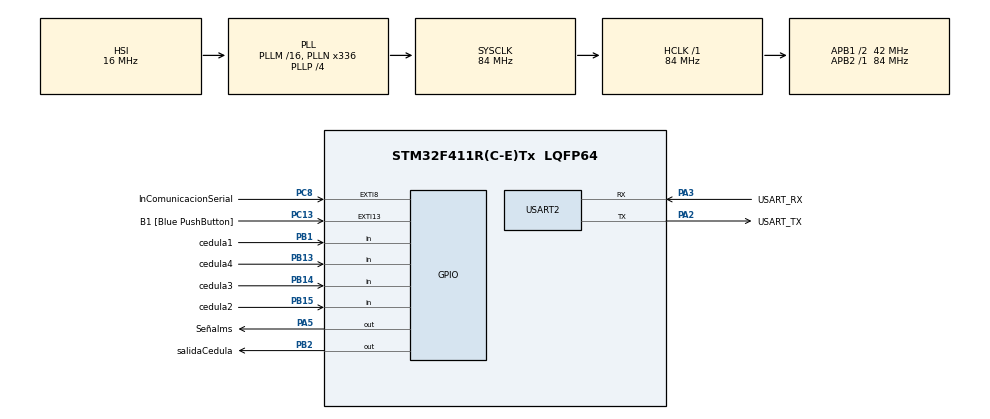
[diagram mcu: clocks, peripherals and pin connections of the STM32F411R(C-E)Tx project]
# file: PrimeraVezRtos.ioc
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FREERTOS.Tasks01=Task1,24,128,SenalCuadrada,Default,NULL,Dynamic,NULL,NULL;Task2,8,128,Cedula,Default,NULL,Dynamic,NULL,NULL;Task3,8,128,Receptor,Default,NULL,Dynamic,NULL,NULL
Mcu.Family=STM32F4
Mcu.Name=STM32F411R(C-E)Tx
Mcu.Package=LQFP64
NVIC.EXTI9_5_IRQn=true\:0\:0\:false\:false\:true\:false\:true\:true\:true
NVIC.PriorityGroup=NVIC_PRIORITYGROUP_4
NVIC.TIM1_TRG_COM_TIM11_IRQn=true\:15\:0\:false\:false\:true\:false\:false\:true\:true
NVIC.TIM3_IRQn=true\:5\:0\:false\:false\:true\:true\:true\:true\:true
NVIC.TIM4_IRQn=true\:5\:0\:false\:false\:true\:true\:true\:true\:true
NVIC.TIM5_IRQn=true\:5\:0\:false\:false\:true\:true\:true\:true\:true
NVIC.TimeBase=TIM1_TRG_COM_TIM11_IRQn
NVIC.TimeBaseIP=TIM11
PA13.GPIO_Label=TMS
PA13.Mode=Trace_Asynchronous_SW
PA13.Signal=SYS_JTMS-SWDIO
PA14.GPIO_Label=TCK
PA14.Mode=Trace_Asynchronous_SW
PA14.Signal=SYS_JTCK-SWCLK
PA2.GPIO_Label=USART_TX
PA2.Mode=Asynchronous
PA2.Signal=USART2_TX
PA3.GPIO_Label=USART_RX
PA3.Mode=Asynchronous
PA3.Signal=USART2_RX
PA5.GPIO_Label=Se\u00F1alms
PA5.GPIO_Speed=GPIO_SPEED_FREQ_HIGH
PA5.Signal=GPIO_Output
PB1.GPIO_Label=cedula1
PB1.GPIO_PuPd=GPIO_PULLDOWN
PB1.Signal=GPIO_Input
PB13.GPIO_Label=cedula4
PB13.GPIO_PuPd=GPIO_PULLDOWN
PB13.Signal=GPIO_Input
PB14.GPIO_Label=cedula3
PB14.GPIO_PuPd=GPIO_PULLDOWN
PB14.Signal=GPIO_Input
PB15.GPIO_Label=cedula2
PB15.GPIO_PuPd=GPIO_PULLDOWN
PB15.Signal=GPIO_Input
PB2.GPIO_Label=salidaCedula
PB2.Signal=GPIO_Output
PB3.GPIO_Label=SWO
PB3.Mode=Trace_Asynchronous_SW
PB3.Signal=SYS_JTDO-SWO
PC13-ANTI_TAMP.GPIO_Label=B1 [Blue PushButton]
PC13-ANTI_TAMP.GPIO_ModeDefaultEXTI=GPIO_MODE_IT_FALLING
PC13-ANTI_TAMP.Signal=GPXTI13
PC14-OSC32_IN.Mode=LSE-External-Oscillator
PC14-OSC32_IN.Signal=RCC_OSC32_IN
PC15-OSC32_OUT.Mode=LSE-External-Oscillator
PC15-OSC32_OUT.Signal=RCC_OSC32_OUT
PC8.GPIO_Label=InComunicacionSerial
PC8.GPIO_ModeDefaultEXTI=GPIO_MODE_IT_FALLING
PC8.Signal=GPXTI8
PH0\ -\ OSC_IN.Mode=HSE-External-Clock-Source
PH0\ -\ OSC_IN.Signal=RCC_OSC_IN
PH1\ -\ OSC_OUT.Mode=HSE-External-Clock-Source
PH1\ -\ OSC_OUT.Signal=RCC_OSC_OUT
ProjectManager.HeapSize=0x200
ProjectManager.StackSize=0x400
ProjectManager.TargetToolchain=STM32CubeIDE
RCC.48MHZClocksFreq_Value=84000000
RCC.AHBFreq_Value=84000000
RCC.APB1CLKDivider=RCC_HCLK_DIV2
RCC.APB1Freq_Value=42000000
RCC.APB1TimFreq_Value=84000000
RCC.APB2Freq_Value=84000000
RCC.APB2TimFreq_Value=84000000
RCC.CortexFreq_Value=84000000
RCC.FLatency-AdvancedSettings=FLASH_LATENCY_2
RCC.HCLKFreq_Value=84000000
RCC.HSE_VALUE=8000000
RCC.HSI_VALUE=16000000
RCC.PLLN=336
RCC.PLLP=RCC_PLLP_DIV4
RCC.SYSCLKFreq_VALUE=84000000
RCC.SYSCLKSource=RCC_SYSCLKSOURCE_PLLCLK
RCC.VCOOutputFreq_Value=336000000
TIM3.AutoReloadPreload=TIM_AUTORELOAD_PRELOAD_ENABLE
TIM3.Period=9000
TIM3.Prescaler=84
TIM4.AutoReloadPreload=TIM_AUTORELOAD_PRELOAD_ENABLE
TIM4.Period=50000
TIM4.Prescaler=84
TIM5.AutoReloadPreload=TIM_AUTORELOAD_PRELOAD_ENABLE
TIM5.Period=208
TIM5.Prescaler=84
USART2.VirtualMode=VM_ASYNC
VP_FREERTOS_VS_CMSIS_V2.Mode=CMSIS_V2
VP_SYS_VS_tim11.Mode=TIM11
VP_TIM3_VS_ClockSourceINT.Mode=Internal
VP_TIM4_VS_ClockSourceINT.Mode=Internal
VP_TIM5_VS_ClockSourceINT.Mode=Internal
board=NUCLEO-F411RE

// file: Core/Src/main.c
/* USER CODE BEGIN Header */
/**
  ******************************************************************************
  * @file           : main.c
  * @brief          : Main program body
  ******************************************************************************
  * @attention
  *
  * Copyright (c) 2023 STMicroelectronics.
  * All rights reserved.
  *
  * This software is licensed under terms that can be found in the LICENSE file
  * in the root directory of this software component.
  * If no LICENSE file comes with this software, it is provided AS-IS.
  *
  ******************************************************************************
  */
/* USER CODE END Header */
#include "main.h"
#include "cmsis_os.h"

TIM_HandleTypeDef htim3;
TIM_HandleTypeDef htim4;
TIM_HandleTypeDef htim5;

UART_HandleTypeDef huart2;

/* Definitions for Task1 */
osThreadId_t Task1Handle;
const osThreadAttr_t Task1_attributes = {
  .name = "Task1",
  .stack_size = 128 * 4,
  .priority = (osPriority_t) osPriorityNormal,
};
/* Definitions for Task2 */
osThreadId_t Task2Handle;
const osThreadAttr_t Task2_attributes = {
  .name = "Task2",
  .stack_size = 128 * 4,
  .priority = (osPriority_t) osPriorityLow,
};
/* Definitions for Task3 */
osThreadId_t Task3Handle;
const osThreadAttr_t Task3_attributes = {
  .name = "Task3",
  .stack_size = 128 * 4,
  .priority = (osPriority_t) osPriorityLow,
};

void SystemClock_Config(void);
static void MX_GPIO_Init(void);
static void MX_USART2_UART_Init(void);
static void MX_TIM3_Init(void);
static void MX_TIM4_Init(void);
static void MX_TIM5_Init(void);
void SenalCuadrada(void *argument);
void Cedula(void *argument);
void Receptor(void *argument);

/* USER CODE BEGIN PFP */
uint8_t A = 0, B = 0, C = 0, D = 0, imprimir = 0;
int contComunicacionTimer = 0, contComunicacionGPIO = 1, cambioARR = 1;
char buffer[40];
int data[9];
/* USER CODE END PFP */

int main(void)
{

  /* MCU Configuration--------------------------------------------------------*/

  /* Reset of all peripherals, Initializes the Flash interface and the Systick. */
  HAL_Init();

  /* Configure the system clock */
  SystemClock_Config();

  /* Initialize all configured peripherals */
  MX_GPIO_Init();
  MX_USART2_UART_Init();
  MX_TIM3_Init();
  MX_TIM4_Init();
  MX_TIM5_Init();

  /* Init scheduler */
  osKernelInitialize();

  /* Create the thread(s) */
  /* creation of Task1 */
  Task1Handle = osThreadNew(SenalCuadrada, NULL, &Task1_attributes);

  /* creation of Task2 */
  Task2Handle = osThreadNew(Cedula, NULL, &Task2_attributes);

  /* creation of Task3 */
  Task3Handle = osThreadNew(Receptor, NULL, &Task3_attributes);

  /* Start scheduler */
  osKernelStart();

  /* We should never get here as control is now taken by the scheduler */
  /* Infinite loop */
  while (1)
  {
  }
}

void SystemClock_Config(void)
{
  RCC_OscInitTypeDef RCC_OscInitStruct = {0};
  RCC_ClkInitTypeDef RCC_ClkInitStruct = {0};

  /** Configure the main internal regulator output voltage
  */
  __HAL_RCC_PWR_CLK_ENABLE();
  __HAL_PWR_VOLTAGESCALING_CONFIG(PWR_REGULATOR_VOLTAGE_SCALE1);

  /** Initializes the RCC Oscillators according to the specified parameters
  * in the RCC_OscInitTypeDef structure.
  */
  RCC_OscInitStruct.OscillatorType = RCC_OSCILLATORTYPE_HSI;
  RCC_OscInitStruct.HSIState = RCC_HSI_ON;
  RCC_OscInitStruct.HSICalibrationValue = RCC_HSICALIBRATION_DEFAULT;
  RCC_OscInitStruct.PLL.PLLState = RCC_PLL_ON;
  RCC_OscInitStruct.PLL.PLLSource = RCC_PLLSOURCE_HSI;
  RCC_OscInitStruct.PLL.PLLM = 16;
  RCC_OscInitStruct.PLL.PLLN = 336;
  RCC_OscInitStruct.PLL.PLLP = RCC_PLLP_DIV4;
  RCC_OscInitStruct.PLL.PLLQ = 4;
  if (HAL_RCC_OscConfig(&RCC_OscInitStruct) != HAL_OK)
  {
    Error_Handler();
  }

  /** Initializes the CPU, AHB and APB buses clocks
  */
  RCC_ClkInitStruct.ClockType = RCC_CLOCKTYPE_HCLK|RCC_CLOCKTYPE_SYSCLK
                              |RCC_CLOCKTYPE_PCLK1|RCC_CLOCKTYPE_PCLK2;
  RCC_ClkInitStruct.SYSCLKSource = RCC_SYSCLKSOURCE_PLLCLK;
  RCC_ClkInitStruct.AHBCLKDivider = RCC_SYSCLK_DIV1;
  RCC_ClkInitStruct.APB1CLKDivider = RCC_HCLK_DIV2;
  RCC_ClkInitStruct.APB2CLKDivider = RCC_HCLK_DIV1;

  if (HAL_RCC_ClockConfig(&RCC_ClkInitStruct, FLASH_LATENCY_2) != HAL_OK)
  {
    Error_Handler();
  }
}

static void MX_TIM3_Init(void)
{

  TIM_ClockConfigTypeDef sClockSourceConfig = {0};
  TIM_MasterConfigTypeDef sMasterConfig = {0};

  htim3.Instance = TIM3;
  htim3.Init.Prescaler = 84;
  htim3.Init.CounterMode = TIM_COUNTERMODE_UP;
  htim3.Init.Period = 9000;
  htim3.Init.ClockDivision = TIM_CLOCKDIVISION_DIV1;
  htim3.Init.AutoReloadPreload = TIM_AUTORELOAD_PRELOAD_ENABLE;
  if (HAL_TIM_Base_Init(&htim3) != HAL_OK)
  {
    Error_Handler();
  }
  sClockSourceConfig.ClockSource = TIM_CLOCKSOURCE_INTERNAL;
  if (HAL_TIM_ConfigClockSource(&htim3, &sClockSourceConfig) != HAL_OK)
  {
    Error_Handler();
  }
  sMasterConfig.MasterOutputTrigger = TIM_TRGO_RESET;
  sMasterConfig.MasterSlaveMode = TIM_MASTERSLAVEMODE_DISABLE;
  if (HAL_TIMEx_MasterConfigSynchronization(&htim3, &sMasterConfig) != HAL_OK)
  {
    Error_Handler();
  }

}

static void MX_TIM4_Init(void)
{

  TIM_ClockConfigTypeDef sClockSourceConfig = {0};
  TIM_MasterConfigTypeDef sMasterConfig = {0};

  htim4.Instance = TIM4;
  htim4.Init.Prescaler = 84;
  htim4.Init.CounterMode = TIM_COUNTERMODE_UP;
  htim4.Init.Period = 50000;
  htim4.Init.ClockDivision = TIM_CLOCKDIVISION_DIV1;
  htim4.Init.AutoReloadPreload = TIM_AUTORELOAD_PRELOAD_ENABLE;
  if (HAL_TIM_Base_Init(&htim4) != HAL_OK)
  {
    Error_Handler();
  }
  sClockSourceConfig.ClockSource = TIM_CLOCKSOURCE_INTERNAL;
  if (HAL_TIM_ConfigClockSource(&htim4, &sClockSourceConfig) != HAL_OK)
  {
    Error_Handler();
  }
  sMasterConfig.MasterOutputTrigger = TIM_TRGO_RESET;
  sMasterConfig.MasterSlaveMode = TIM_MASTERSLAVEMODE_DISABLE;
  if (HAL_TIMEx_MasterConfigSynchronization(&htim4, &sMasterConfig) != HAL_OK)
  {
    Error_Handler();
  }

}

static void MX_TIM5_Init(void)
{

  TIM_ClockConfigTypeDef sClockSourceConfig = {0};
  TIM_MasterConfigTypeDef sMasterConfig = {0};

  htim5.Instance = TIM5;
  htim5.Init.Prescaler = 84;
  htim5.Init.CounterMode = TIM_COUNTERMODE_UP;
  htim5.Init.Period = 208;
  htim5.Init.ClockDivision = TIM_CLOCKDIVISION_DIV1;
  htim5.Init.AutoReloadPreload = TIM_AUTORELOAD_PRELOAD_ENABLE;
  if (HAL_TIM_Base_Init(&htim5) != HAL_OK)
  {
    Error_Handler();
  }
  sClockSourceConfig.ClockSource = TIM_CLOCKSOURCE_INTERNAL;
  if (HAL_TIM_ConfigClockSource(&htim5, &sClockSourceConfig) != HAL_OK)
  {
    Error_Handler();
  }
  sMasterConfig.MasterOutputTrigger = TIM_TRGO_RESET;
  sMasterConfig.MasterSlaveMode = TIM_MASTERSLAVEMODE_DISABLE;
  if (HAL_TIMEx_MasterConfigSynchronization(&htim5, &sMasterConfig) != HAL_OK)
  {
    Error_Handler();
  }

}

static void MX_USART2_UART_Init(void)
{

  huart2.Instance = USART2;
  huart2.Init.BaudRate = 115200;
  huart2.Init.WordLength = UART_WORDLENGTH_8B;
  huart2.Init.StopBits = UART_STOPBITS_1;
  huart2.Init.Parity = UART_PARITY_NONE;
  huart2.Init.Mode = UART_MODE_TX_RX;
  huart2.Init.HwFlowCtl = UART_HWCONTROL_NONE;
  huart2.Init.OverSampling = UART_OVERSAMPLING_16;
  if (HAL_UART_Init(&huart2) != HAL_OK)
  {
    Error_Handler();
  }

}

static void MX_GPIO_Init(void)
{
  GPIO_InitTypeDef GPIO_InitStruct = {0};

  /* GPIO Ports Clock Enable */
  __HAL_RCC_GPIOC_CLK_ENABLE();
  __HAL_RCC_GPIOH_CLK_ENABLE();
  __HAL_RCC_GPIOA_CLK_ENABLE();
  __HAL_RCC_GPIOB_CLK_ENABLE();

  /*Configure GPIO pin Output Level */
  HAL_GPIO_WritePin(Se_alms_GPIO_Port, Se_alms_Pin, GPIO_PIN_RESET);

  /*Configure GPIO pin Output Level */
  HAL_GPIO_WritePin(salidaCedula_GPIO_Port, salidaCedula_Pin, GPIO_PIN_RESET);

  /*Configure GPIO pins : B1_Pin InComunicacionSerial_Pin */
  GPIO_InitStruct.Pin = B1_Pin|InComunicacionSerial_Pin;
  GPIO_InitStruct.Mode = GPIO_MODE_IT_FALLING;
  GPIO_InitStruct.Pull = GPIO_NOPULL;
  HAL_GPIO_Init(GPIOC, &GPIO_InitStruct);

  /*Configure GPIO pin : Se_alms_Pin */
  GPIO_InitStruct.Pin = Se_alms_Pin;
  GPIO_InitStruct.Mode = GPIO_MODE_OUTPUT_PP;
  GPIO_InitStruct.Pull = GPIO_NOPULL;
  GPIO_InitStruct.Speed = GPIO_SPEED_FREQ_HIGH;
  HAL_GPIO_Init(Se_alms_GPIO_Port, &GPIO_InitStruct);

  /*Configure GPIO pins : cedula1_Pin cedula4_Pin cedula3_Pin cedula2_Pin */
  GPIO_InitStruct.Pin = cedula1_Pin|cedula4_Pin|cedula3_Pin|cedula2_Pin;
  GPIO_InitStruct.Mode = GPIO_MODE_INPUT;
  GPIO_InitStruct.Pull = GPIO_PULLDOWN;
  HAL_GPIO_Init(GPIOB, &GPIO_InitStruct);

  /*Configure GPIO pin : salidaCedula_Pin */
  GPIO_InitStruct.Pin = salidaCedula_Pin;
  GPIO_InitStruct.Mode = GPIO_MODE_OUTPUT_PP;
  GPIO_InitStruct.Pull = GPIO_NOPULL;
  GPIO_InitStruct.Speed = GPIO_SPEED_FREQ_LOW;
  HAL_GPIO_Init(salidaCedula_GPIO_Port, &GPIO_InitStruct);

  /* EXTI interrupt init*/
  HAL_NVIC_SetPriority(EXTI9_5_IRQn, 0, 0);
  HAL_NVIC_EnableIRQ(EXTI9_5_IRQn);

}

void SenalCuadrada(void *argument){

  for(;;){
	HAL_GPIO_TogglePin(GPIOA, GPIO_PIN_5);
    osDelay(9);
  }
}

void Cedula(void *argument){

  for(;;){

	A = HAL_GPIO_ReadPin(GPIOB, GPIO_PIN_1);
	B = HAL_GPIO_ReadPin(GPIOB, GPIO_PIN_15);
	C = HAL_GPIO_ReadPin(GPIOB, GPIO_PIN_14);
	D = HAL_GPIO_ReadPin(GPIOB, GPIO_PIN_13); // bit derecha ABCD

	if(( !A && !B && !C ) || ( D && !B && !C ) || ( !A && B && !D )){
		HAL_GPIO_WritePin(GPIOB, GPIO_PIN_2, GPIO_PIN_SET);
	}else{
		HAL_GPIO_WritePin(GPIOB, GPIO_PIN_2, GPIO_PIN_RESET);
	}
	osDelay(50);
  }
}

void Receptor(void *argument){

  for(;;){
	  switch(cambioARR){
	  	  	  case 1:
	  	  		  TIM5->ARR = 208;
	  	  		  cambioARR = 0;
	  	  		  break;
	  	  	  case 2:
	  	  		  TIM5->ARR = 312;
	  	  		  cambioARR = 0;
	  	  		  break;
	  	  }

	  	  if(imprimir){
	  		  snprintf(buffer, sizeof(buffer), "El valor es: %d %d %d %d %d %d %d %d\r\n", data[1], data[2], data[3], data[4], data[5], data[6], data[7], data[8]);
	  		  HAL_UART_Transmit(&huart2, (uint8_t*)buffer, strlen(buffer), HAL_MAX_DELAY);
	  		  imprimir = 0;
	  	  }

  }
}

void HAL_GPIO_EXTI_Callback(uint16_t GPIO_Pin) {

	if(contComunicacionGPIO){
		HAL_TIM_Base_Start_IT(&htim5);
		contComunicacionGPIO = 0;
	}

}

void HAL_TIM_PeriodElapsedCallback(TIM_HandleTypeDef *htim)
{
  if (htim->Instance == TIM11) {
    HAL_IncTick();
  }
  /* USER CODE BEGIN Callback 1 */
  if(htim == &htim5){
  		if(TIM5->ARR == 312) cambioARR = 1;
  		if(contComunicacionTimer == 9){
  			contComunicacionTimer = 0;
  			contComunicacionGPIO = 1;
  			cambioARR = 2;
  			imprimir = 1;
  			HAL_TIM_Base_Stop_IT(&htim5);
  		}
  		data[contComunicacionTimer] = HAL_GPIO_ReadPin(GPIOC, GPIO_PIN_8);
  		++contComunicacionTimer;

  	}
  /* USER CODE END Callback 1 */
}

void Error_Handler(void)
{
  __disable_irq();
  while (1)
  {
  }
}
